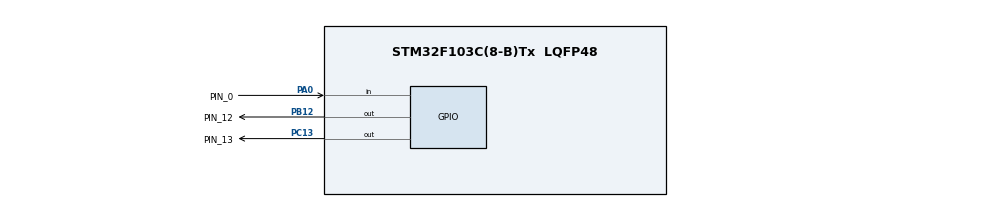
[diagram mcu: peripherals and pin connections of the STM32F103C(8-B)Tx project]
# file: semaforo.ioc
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Mcu.Family=STM32F1
Mcu.Name=STM32F103C(8-B)Tx
Mcu.Package=LQFP48
NVIC.PriorityGroup=NVIC_PRIORITYGROUP_4
PA0-WKUP.GPIO_Label=PIN_0
PA0-WKUP.GPIO_PuPd=GPIO_PULLDOWN
PA0-WKUP.Signal=GPIO_Input
PB12.GPIO_Label=PIN_12
PB12.GPIO_PuPd=GPIO_PULLUP
PB12.Signal=GPIO_Output
PC13-TAMPER-RTC.GPIO_Label=PIN_13
PC13-TAMPER-RTC.GPIO_PuPd=GPIO_PULLUP
PC13-TAMPER-RTC.Signal=GPIO_Output
ProjectManager.HeapSize=0x200
ProjectManager.StackSize=0x400
ProjectManager.TargetToolchain=STM32CubeIDE
RCC.APB1Freq_Value=8000000
RCC.APB2Freq_Value=8000000
VP_SYS_VS_ND.Mode=No_Debug
board=custom

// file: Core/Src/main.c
/* USER CODE BEGIN Header */
/**
  ******************************************************************************
  * @file           : main.c
  * @brief          : Main program body
  ******************************************************************************
  * @attention
  *
  * Copyright (c) 2024 STMicroelectronics.
  * All rights reserved.
  *
  * This software is licensed under terms that can be found in the LICENSE file
  * in the root directory of this software component.
  * If no LICENSE file comes with this software, it is provided AS-IS.
  *
  ******************************************************************************
  */
/* USER CODE END Header */

#include <stdint.h>  // Asegúrate de incluir esta librería

#include "main.h"
uint32_t tiempo_inicio = 0;  // Definición de la variable
int estado = 0;  // Estado inicial: 0 = Verde, 1 = Verde Parpadeante, 2 = Rojo, 3 = Rojo Parpadeante
int solicitud = 0;  // Bandera para indicar si se ha presionado el botón

void SystemClock_Config(void);
static void MX_GPIO_Init(void);
void semaforo(void);

int main(void)
{

  /* MCU Configuration--------------------------------------------------------*/

  /* Reset of all peripherals, Initializes the Flash interface and the Systick. */
  HAL_Init();

  /* USER CODE BEGIN Init */
  HAL_GPIO_WritePin(GPIOC, GPIO_PIN_13, GPIO_PIN_RESET); // En lugar de PIN_13_GPIO_Port, PIN_13_Pin
  HAL_GPIO_WritePin(GPIOB, GPIO_PIN_12, GPIO_PIN_RESET); // En lugar de PIN_12_GPIO_Port, PIN_12_Pin
  HAL_GPIO_ReadPin(GPIOA, GPIO_PIN_0); // En lugar de PIN_0_GPIO_Port, PIN_0_Pin

  /* USER CODE END Init */

  /* Configure the system clock */
  SystemClock_Config();

  /* Initialize all configured peripherals */
  MX_GPIO_Init();

  /* Infinite loop */
  /* USER CODE BEGIN WHILE */
  while (1)
  {

    semaforo();  // Controla la lógica del semáforo
  }
}

void SystemClock_Config(void)
{
  RCC_OscInitTypeDef RCC_OscInitStruct = {0};
  RCC_ClkInitTypeDef RCC_ClkInitStruct = {0};

  /** Initializes the RCC Oscillators according to the specified parameters
  * in the RCC_OscInitTypeDef structure.
  */
  RCC_OscInitStruct.OscillatorType = RCC_OSCILLATORTYPE_HSI;
  RCC_OscInitStruct.HSIState = RCC_HSI_ON;
  RCC_OscInitStruct.HSICalibrationValue = RCC_HSICALIBRATION_DEFAULT;
  RCC_OscInitStruct.PLL.PLLState = RCC_PLL_NONE;
  if (HAL_RCC_OscConfig(&RCC_OscInitStruct) != HAL_OK)
  {
    Error_Handler();
  }

  /** Initializes the CPU, AHB and APB buses clocks
  */
  RCC_ClkInitStruct.ClockType = RCC_CLOCKTYPE_HCLK|RCC_CLOCKTYPE_SYSCLK
                              |RCC_CLOCKTYPE_PCLK1|RCC_CLOCKTYPE_PCLK2;
  RCC_ClkInitStruct.SYSCLKSource = RCC_SYSCLKSOURCE_HSI;
  RCC_ClkInitStruct.AHBCLKDivider = RCC_SYSCLK_DIV1;
  RCC_ClkInitStruct.APB1CLKDivider = RCC_HCLK_DIV1;
  RCC_ClkInitStruct.APB2CLKDivider = RCC_HCLK_DIV1;

  if (HAL_RCC_ClockConfig(&RCC_ClkInitStruct, FLASH_LATENCY_0) != HAL_OK)
  {
    Error_Handler();
  }
}

static void MX_GPIO_Init(void)
{
  GPIO_InitTypeDef GPIO_InitStruct = {0};

  /* GPIO Ports Clock Enable */
  __HAL_RCC_GPIOC_CLK_ENABLE();
  __HAL_RCC_GPIOA_CLK_ENABLE();
  __HAL_RCC_GPIOB_CLK_ENABLE();

  /*Configure GPIO pin Output Level */
  HAL_GPIO_WritePin(GPIOC, GPIO_PIN_13, GPIO_PIN_RESET);

  /*Configure GPIO pin Output Level */
  HAL_GPIO_WritePin(GPIOB, GPIO_PIN_12, GPIO_PIN_RESET);
  /*Configure GPIO pin : PIN_13_Pin */
  GPIO_InitStruct.Pin = PIN_13_Pin;
  GPIO_InitStruct.Mode = GPIO_MODE_OUTPUT_PP;
  GPIO_InitStruct.Pull = GPIO_PULLUP;
  GPIO_InitStruct.Speed = GPIO_SPEED_FREQ_LOW;
  HAL_GPIO_Init(PIN_13_GPIO_Port, &GPIO_InitStruct);

  /*Configure GPIO pin : PIN_0_Pin */
  GPIO_InitStruct.Pin = PIN_0_Pin;
  GPIO_InitStruct.Mode = GPIO_MODE_INPUT;
  GPIO_InitStruct.Pull = GPIO_PULLDOWN;
  HAL_GPIO_Init(PIN_0_GPIO_Port, &GPIO_InitStruct);

  /*Configure GPIO pin : PIN_12_Pin */
  GPIO_InitStruct.Pin = PIN_12_Pin;
  GPIO_InitStruct.Mode = GPIO_MODE_OUTPUT_PP;
  GPIO_InitStruct.Pull = GPIO_PULLUP;
  GPIO_InitStruct.Speed = GPIO_SPEED_FREQ_LOW;
  HAL_GPIO_Init(PIN_12_GPIO_Port, &GPIO_InitStruct);

}

void Error_Handler(void)
{
  __disable_irq();
  while (1)
  {
  }
}
